VERSION ""

NS_ :

BS_:

BU_: Vector__XXX

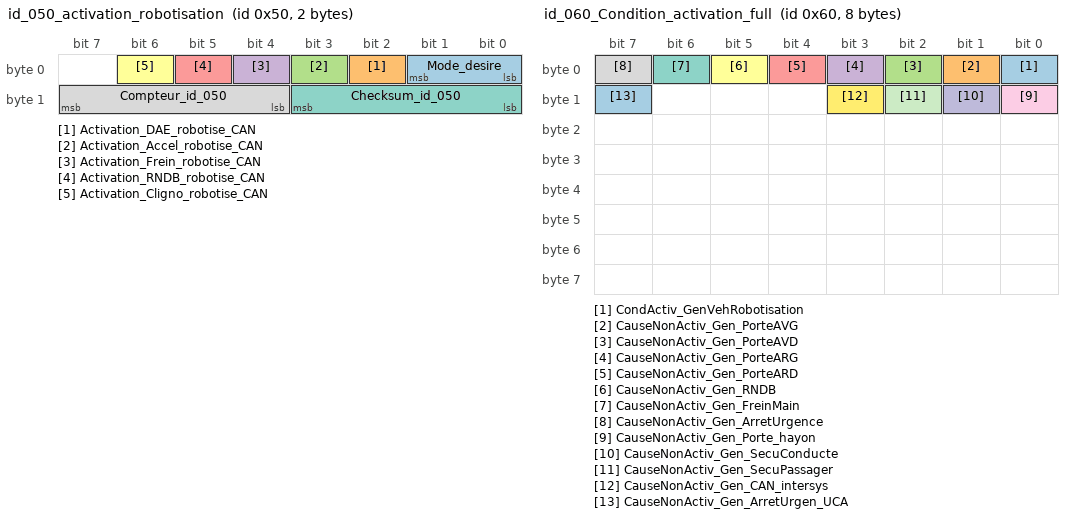
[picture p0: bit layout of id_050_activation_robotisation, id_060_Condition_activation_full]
BO_ 80 id_050_activation_robotisation: 2 Vector__XXX
SG_ Mode_desire : 1|2@0+ (1,0) [0|3] "-" Vector__XXX
SG_ Activation_DAE_robotise_CAN : 2|1@0+ (1,0) [0|1] "-" Vector__XXX
SG_ Activation_Accel_robotise_CAN : 3|1@0+ (1,0) [0|1] "-" Vector__XXX
SG_ Activation_Frein_robotise_CAN : 4|1@0+ (1,0) [0|1] "-" Vector__XXX
SG_ Activation_RNDB_robotise_CAN : 5|1@0+ (1,0) [0|1] "-" Vector__XXX
SG_ Activation_Cligno_robotise_CAN : 6|1@0+ (1,0) [0|1] "-" Vector__XXX
SG_ Checksum_id_050 : 11|4@0+ (1,0) [0|15] "CRC" Vector__XXX
SG_ Compteur_id_050 : 15|4@0+ (1,0) [0|15] "-" Vector__XXX

BO_ 96 id_060_Condition_activation_full: 8 Vector__XXX
SG_ CondActiv_GenVehRobotisation : 0|1@0+ (1,0) [0|1] "-" Vector__XXX
SG_ CauseNonActiv_Gen_PorteAVG : 1|1@0+ (1,0) [0|1] "-" Vector__XXX
SG_ CauseNonActiv_Gen_PorteAVD : 2|1@0+ (1,0) [0|1] "-" Vector__XXX
SG_ CauseNonActiv_Gen_PorteARG : 3|1@0+ (1,0) [0|1] "-" Vector__XXX
SG_ CauseNonActiv_Gen_PorteARD : 4|1@0+ (1,0) [0|1] "-" Vector__XXX
SG_ CauseNonActiv_Gen_RNDB : 5|1@0+ (1,0) [0|1] "-" Vector__XXX
SG_ CauseNonActiv_Gen_FreinMain : 6|1@0+ (1,0) [0|1] "-" Vector__XXX
SG_ CauseNonActiv_Gen_ArretUrgence : 7|1@0+ (1,0) [0|1] "-" Vector__XXX
SG_ CauseNonActiv_Gen_Porte_hayon : 8|1@0+ (1,0) [0|1] "-" Vector__XXX
SG_ CauseNonActiv_Gen_SecuConducte : 9|1@0+ (1,0) [0|1] "-" Vector__XXX
SG_ CauseNonActiv_Gen_SecuPassager : 10|1@0+ (1,0) [0|1] "-" Vector__XXX
SG_ CauseNonActiv_Gen_CAN_intersys : 11|1@0+ (1,0) [0|1] "-" Vector__XXX
SG_ CauseNonActiv_Gen_ArretUrgen_UCA : 15|1@0+ (1,0) [0|1] "-" Vector__XXX

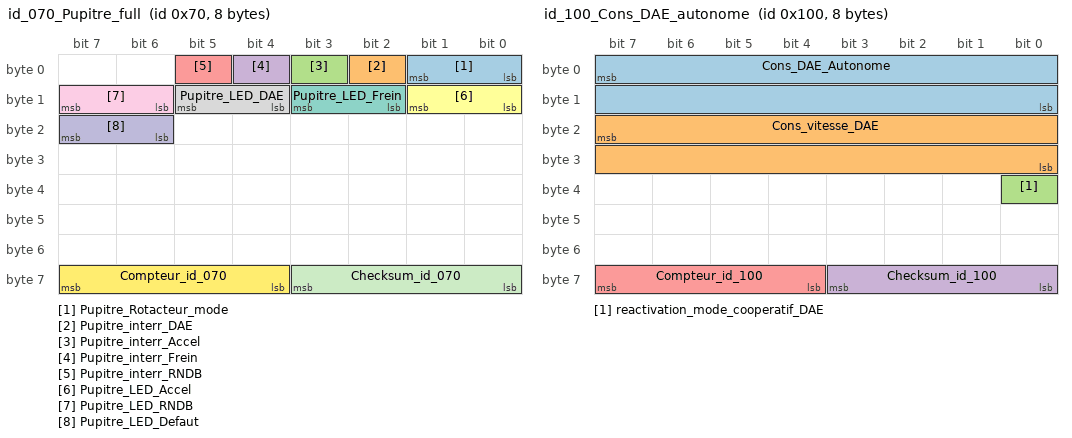
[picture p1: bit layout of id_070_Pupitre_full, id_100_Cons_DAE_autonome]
BO_ 112 id_070_Pupitre_full: 8 Vector__XXX
SG_ Pupitre_Rotacteur_mode : 1|2@0+ (1,0) [0|3] "-" Vector__XXX
SG_ Pupitre_interr_DAE : 2|1@0+ (1,0) [0|1] "-" Vector__XXX
SG_ Pupitre_interr_Accel : 3|1@0+ (1,0) [0|1] "-" Vector__XXX
SG_ Pupitre_interr_Frein : 4|1@0+ (1,0) [0|1] "-" Vector__XXX
SG_ Pupitre_interr_RNDB : 5|1@0+ (1,0) [0|1] "-" Vector__XXX
SG_ Pupitre_LED_Accel : 9|2@0+ (1,0) [0|3] "-" Vector__XXX
SG_ Pupitre_LED_Frein : 11|2@0+ (1,0) [0|3] "-" Vector__XXX
SG_ Pupitre_LED_DAE : 13|2@0+ (1,0) [0|3] "-" Vector__XXX
SG_ Pupitre_LED_RNDB : 15|2@0+ (1,0) [0|3] "-" Vector__XXX
SG_ Pupitre_LED_Defaut : 23|2@0+ (1,0) [0|3] "-" Vector__XXX
SG_ Checksum_id_070 : 59|4@0+ (1,0) [0|15] "CRC" Vector__XXX
SG_ Compteur_id_070 : 63|4@0+ (1,0) [0|15] "-" Vector__XXX

BO_ 256 id_100_Cons_DAE_autonome: 8 Vector__XXX
SG_ Cons_DAE_Autonome : 7|16@0+ (0.1,-720) [-720|5833.5] "°volant" Vector__XXX
SG_ Cons_vitesse_DAE : 23|16@0+ (0.1,0) [0|6553.5] "°/s" Vector__XXX
SG_ reactivation_mode_cooperatif_DAE : 32|1@0+ (1,0) [0|1] "-" Vector__XXX
SG_ Checksum_id_100 : 59|4@0+ (1,0) [0|15] "CRC" Vector__XXX
SG_ Compteur_id_100 : 63|4@0+ (1,0) [0|15] "-" Vector__XXX

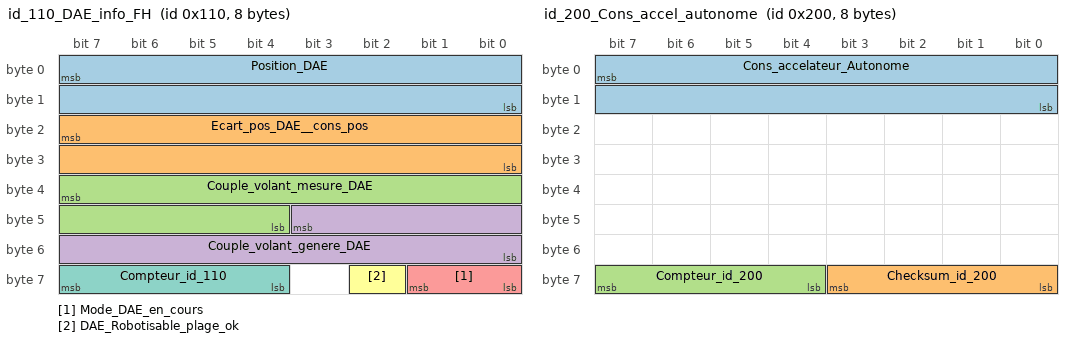
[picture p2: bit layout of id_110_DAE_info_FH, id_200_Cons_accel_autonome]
BO_ 272 id_110_DAE_info_FH: 8 Vector__XXX
SG_ Position_DAE : 7|16@0+ (0.1,-720) [-720|5833.5] "°volant" Vector__XXX
SG_ Ecart_pos_DAE__cons_pos : 23|16@0+ (0.1,-720) [-720|5833.5] "°volant" Vector__XXX
SG_ Couple_volant_mesure_DAE : 39|12@0+ (0.1,-200) [-200|209.5] "%" Vector__XXX
SG_ Couple_volant_genere_DAE : 43|12@0+ (0.1,-200) [-200|209.5] "%" Vector__XXX
SG_ Mode_DAE_en_cours : 57|2@0+ (1,0) [0|3] "-" Vector__XXX
SG_ DAE_Robotisable_plage_ok : 58|1@0+ (1,0) [0|1] "-" Vector__XXX
SG_ Compteur_id_110 : 63|4@0+ (1,0) [0|15] "-" Vector__XXX

BO_ 273 id_111_DAE_info_FH: 8 Vector__XXX
SG_ Butee_maxi_DAE_G_autorise : 7|16@0+ (0.1,-720) [-720|5833.5] "°volant" Vector__XXX
SG_ Butee_maxi_DAE_D_autorise : 23|16@0+ (0.1,-720) [-720|5833.5] "°volant" Vector__XXX
SG_ ErreurButeeDAE_gauche_atteinte : 32|1@0+ (1,0) [0|1] "-" Vector__XXX
SG_ ErreurButeeDAE_droite_atteinte : 33|1@0+ (1,0) [0|1] "-" Vector__XXX
SG_ ErreurCaptDAE_origine_couple_1 : 34|1@0+ (1,0) [0|1] "-" Vector__XXX
SG_ ErreurCapteur_DAE_incoh_sign1_2 : 35|1@0+ (1,0) [0|1] "-" Vector__XXX
SG_ ErreurPerte_CAN_intersystem_DAE : 36|1@0+ (1,0) [0|1] "-" Vector__XXX
SG_ CauseDesactDAE_RepriseManu : 40|1@0+ (1,0) [0|1] "-" Vector__XXX
SG_ CauseDesactDAE_RepriseExterne : 41|1@0+ (1,0) [0|1] "-" Vector__XXX
SG_ CauseDesactDAE_PbCANRot_timeout : 42|1@0+ (1,0) [0|1] "-" Vector__XXX
SG_ CauseDesactDAE_PbCANRob_chk : 43|1@0+ (1,0) [0|1] "-" Vector__XXX
SG_ CauseDesactDAE_PbCANRob_Cpt : 44|1@0+ (1,0) [0|1] "-" Vector__XXX
SG_ CauseDesactDAE_PbCapteurOri : 45|1@0+ (1,0) [0|1] "-" Vector__XXX
SG_ CauseDesactDAE_RepriseManuCoop : 46|1@0+ (1,0) [0|1] "-" Vector__XXX
SG_ DAE_DmdPilotageLED : 49|2@0+ (1,0) [0|3] "-" Vector__XXX
SG_ DAE_DmdPilotageBuzzer : 52|3@0+ (1,0) [0|7] "-" Vector__XXX
SG_ DAE_DmdPilotageLED_Dft : 54|2@0+ (1,0) [0|3] "-" Vector__XXX
SG_ Compteur_id_111 : 63|4@0+ (1,0) [0|15] "-" Vector__XXX

BO_ 512 id_200_Cons_accel_autonome: 8 Vector__XXX
SG_ Cons_accelateur_Autonome : 7|16@0+ (0.1,0) [0|6553.5] "0-100%" Vector__XXX
SG_ Checksum_id_200 : 59|4@0+ (1,0) [0|15] "CRC" Vector__XXX
SG_ Compteur_id_200 : 63|4@0+ (1,0) [0|15] "-" Vector__XXX

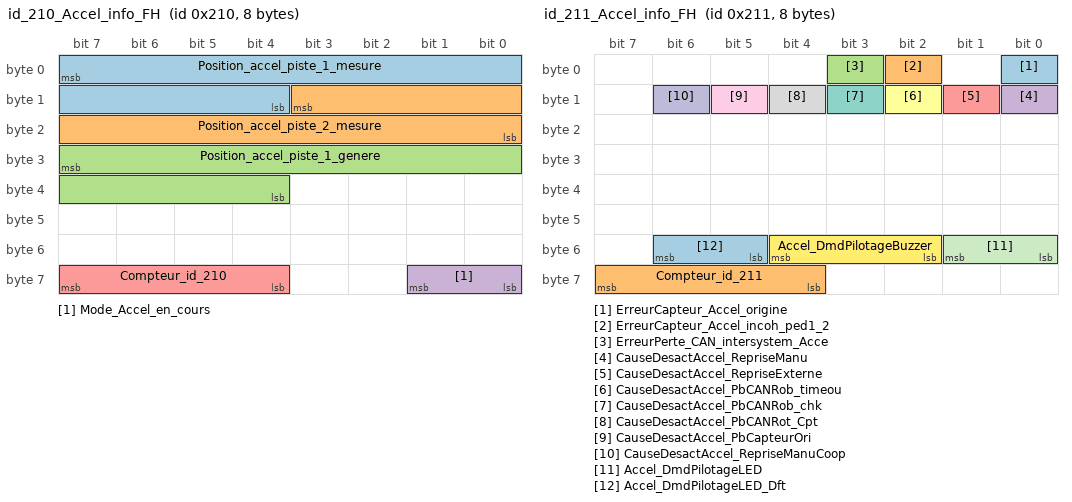
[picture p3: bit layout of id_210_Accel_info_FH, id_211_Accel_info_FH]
BO_ 528 id_210_Accel_info_FH: 8 Vector__XXX
SG_ Position_accel_piste_1_mesure : 7|12@0+ (0.1,0) [0|409.5] "0-100%" Vector__XXX
SG_ Position_accel_piste_2_mesure : 11|12@0+ (0.1,0) [0|409.5] "0-100%" Vector__XXX
SG_ Position_accel_piste_1_genere : 31|12@0+ (0.1,0) [0|409.5] "0-100%" Vector__XXX
SG_ Mode_Accel_en_cours : 57|2@0+ (1,0) [0|3] "-" Vector__XXX
SG_ Compteur_id_210 : 63|4@0+ (1,0) [0|15] "-" Vector__XXX

BO_ 529 id_211_Accel_info_FH: 8 Vector__XXX
SG_ ErreurCapteur_Accel_origine : 0|1@0+ (1,0) [0|1] "-" Vector__XXX
SG_ ErreurCapteur_Accel_incoh_ped1_2 : 2|1@0+ (1,0) [0|1] "-" Vector__XXX
SG_ ErreurPerte_CAN_intersystem_Acce : 3|1@0+ (1,0) [0|1] "-" Vector__XXX
SG_ CauseDesactAccel_RepriseManu : 8|1@0+ (1,0) [0|1] "-" Vector__XXX
SG_ CauseDesactAccel_RepriseExterne : 9|1@0+ (1,0) [0|1] "-" Vector__XXX
SG_ CauseDesactAccel_PbCANRob_timeou : 10|1@0+ (1,0) [0|1] "-" Vector__XXX
SG_ CauseDesactAccel_PbCANRob_chk : 11|1@0+ (1,0) [0|1] "-" Vector__XXX
SG_ CauseDesactAccel_PbCANRot_Cpt : 12|1@0+ (1,0) [0|1] "-" Vector__XXX
SG_ CauseDesactAccel_PbCapteurOri : 13|1@0+ (1,0) [0|1] "-" Vector__XXX
SG_ CauseDesactAccel_RepriseManuCoop : 14|1@0+ (1,0) [0|1] "-" Vector__XXX
SG_ Accel_DmdPilotageLED : 49|2@0+ (1,0) [0|3] "-" Vector__XXX
SG_ Accel_DmdPilotageBuzzer : 52|3@0+ (1,0) [0|7] "-" Vector__XXX
SG_ Accel_DmdPilotageLED_Dft : 54|2@0+ (1,0) [0|3] "-" Vector__XXX
SG_ Compteur_id_211 : 63|4@0+ (1,0) [0|15] "-" Vector__XXX

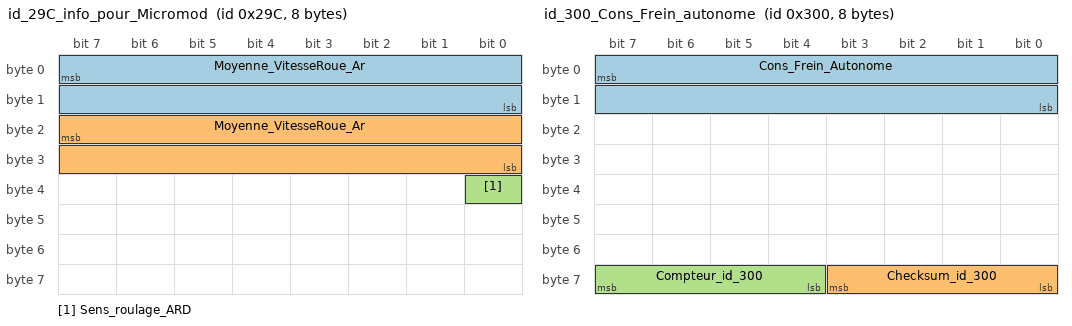
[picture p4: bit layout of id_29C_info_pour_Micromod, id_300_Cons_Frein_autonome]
BO_ 668 id_29C_info_pour_Micromod: 8 Vector__XXX
SG_ Moyenne_VitesseRoue_Ar : 7|16@0+ (0.0417,0) [0|2732.8095] "rpmg" Vector__XXX
SG_ Moyenne_VitesseRoue_Ar : 23|16@0+ (0.0417,0) [0|2732.8095] "rpmd" Vector__XXX
SG_ Sens_roulage_ARD : 32|1@0+ (1,0) [0|1] "-" Vector__XXX

BO_ 768 id_300_Cons_Frein_autonome: 8 Vector__XXX
SG_ Cons_Frein_Autonome : 7|16@0+ (0.1,0) [0|6553.5] "bars" Vector__XXX
SG_ Checksum_id_300 : 59|4@0+ (1,0) [0|15] "CRC" Vector__XXX
SG_ Compteur_id_300 : 63|4@0+ (1,0) [0|15] "-" Vector__XXX

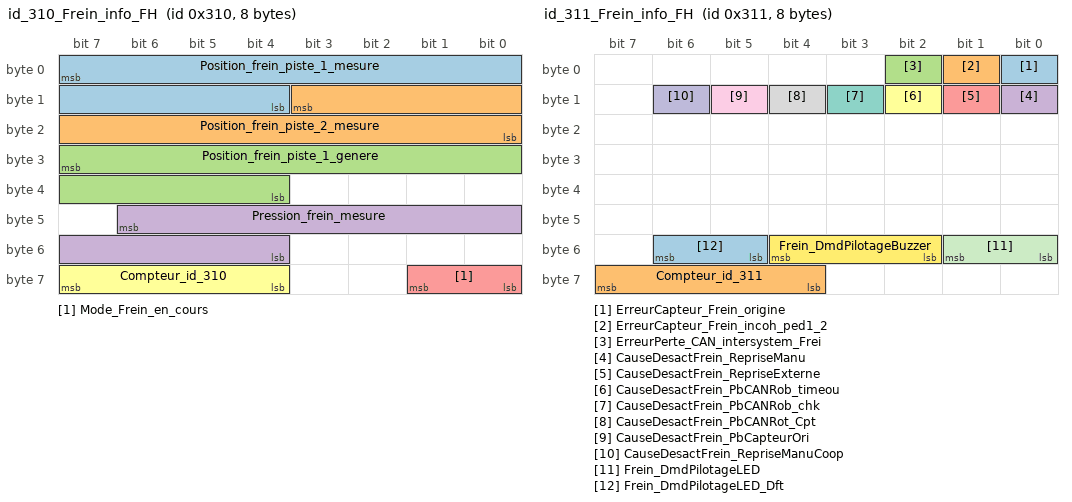
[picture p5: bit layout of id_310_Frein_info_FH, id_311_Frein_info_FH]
BO_ 784 id_310_Frein_info_FH: 8 Vector__XXX
SG_ Position_frein_piste_1_mesure : 7|12@0+ (1,0) [0|4095] "SENT" Vector__XXX
SG_ Position_frein_piste_2_mesure : 11|12@0+ (1,0) [0|4095] "µs" Vector__XXX
SG_ Position_frein_piste_1_genere : 31|12@0+ (1,0) [0|4095] "SENT" Vector__XXX
SG_ Pression_frein_mesure : 46|11@0+ (0.1,0) [0|204.7] "bars" Vector__XXX
SG_ Mode_Frein_en_cours : 57|2@0+ (1,0) [0|3] "-" Vector__XXX
SG_ Compteur_id_310 : 63|4@0+ (1,0) [0|15] "-" Vector__XXX

BO_ 785 id_311_Frein_info_FH: 8 Vector__XXX
SG_ ErreurCapteur_Frein_origine : 0|1@0+ (1,0) [0|1] "-" Vector__XXX
SG_ ErreurCapteur_Frein_incoh_ped1_2 : 1|1@0+ (1,0) [0|1] "-" Vector__XXX
SG_ ErreurPerte_CAN_intersystem_Frei : 2|1@0+ (1,0) [0|1] "-" Vector__XXX
SG_ CauseDesactFrein_RepriseManu : 8|1@0+ (1,0) [0|1] "-" Vector__XXX
SG_ CauseDesactFrein_RepriseExterne : 9|1@0+ (1,0) [0|1] "-" Vector__XXX
SG_ CauseDesactFrein_PbCANRob_timeou : 10|1@0+ (1,0) [0|1] "-" Vector__XXX
SG_ CauseDesactFrein_PbCANRob_chk : 11|1@0+ (1,0) [0|1] "-" Vector__XXX
SG_ CauseDesactFrein_PbCANRot_Cpt : 12|1@0+ (1,0) [0|1] "-" Vector__XXX
SG_ CauseDesactFrein_PbCapteurOri : 13|1@0+ (1,0) [0|1] "-" Vector__XXX
SG_ CauseDesactFrein_RepriseManuCoop : 14|1@0+ (1,0) [0|1] "-" Vector__XXX
SG_ Frein_DmdPilotageLED : 49|2@0+ (1,0) [0|3] "-" Vector__XXX
SG_ Frein_DmdPilotageBuzzer : 52|3@0+ (1,0) [0|7] "-" Vector__XXX
SG_ Frein_DmdPilotageLED_Dft : 54|2@0+ (1,0) [0|3] "-" Vector__XXX
SG_ Compteur_id_311 : 63|4@0+ (1,0) [0|15] "-" Vector__XXX

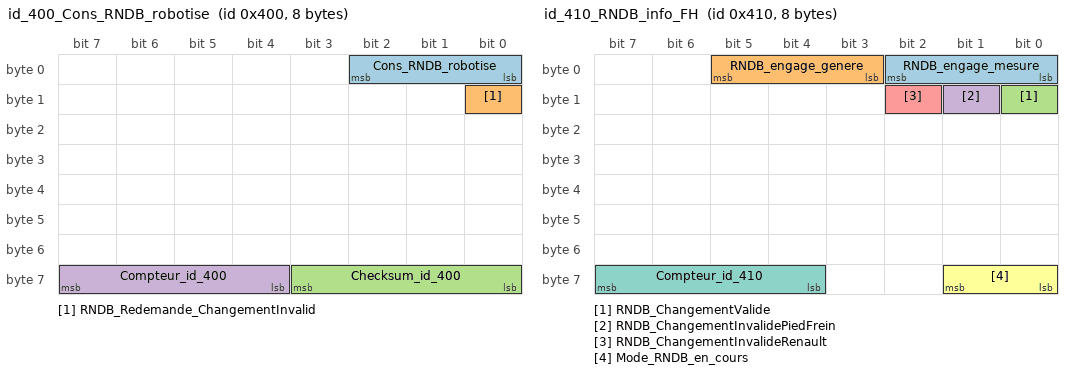
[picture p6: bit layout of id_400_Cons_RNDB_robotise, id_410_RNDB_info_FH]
BO_ 1024 id_400_Cons_RNDB_robotise: 8 Vector__XXX
SG_ Cons_RNDB_robotise : 2|3@0+ (1,0) [0|7] "-" Vector__XXX
SG_ RNDB_Redemande_ChangementInvalid : 8|1@0+ (1,0) [0|1] "-" Vector__XXX
SG_ Checksum_id_400 : 59|4@0+ (1,0) [0|15] "CRC" Vector__XXX
SG_ Compteur_id_400 : 63|4@0+ (1,0) [0|15] "-" Vector__XXX

BO_ 1040 id_410_RNDB_info_FH: 8 Vector__XXX
SG_ RNDB_engage_mesure : 2|3@0+ (1,0) [0|7] "-" Vector__XXX
SG_ RNDB_engage_genere : 5|3@0+ (1,0) [0|7] "-" Vector__XXX
SG_ RNDB_ChangementValide : 8|1@0+ (1,0) [0|1] "-" Vector__XXX
SG_ RNDB_ChangementInvalidePiedFrein : 9|1@0+ (1,0) [0|1] "-" Vector__XXX
SG_ RNDB_ChangementInvalideRenault : 10|1@0+ (1,0) [0|1] "-" Vector__XXX
SG_ Mode_RNDB_en_cours : 57|2@0+ (1,0) [0|3] "-" Vector__XXX
SG_ Compteur_id_410 : 63|4@0+ (1,0) [0|15] "-" Vector__XXX

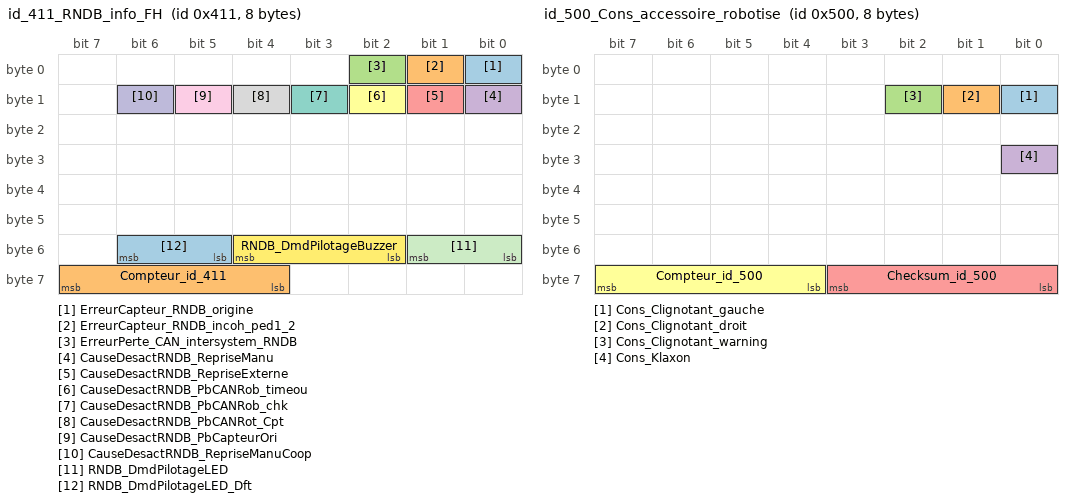
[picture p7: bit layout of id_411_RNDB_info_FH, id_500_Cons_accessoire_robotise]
BO_ 1041 id_411_RNDB_info_FH: 8 Vector__XXX
SG_ ErreurCapteur_RNDB_origine : 0|1@0+ (1,0) [0|1] "-" Vector__XXX
SG_ ErreurCapteur_RNDB_incoh_ped1_2 : 1|1@0+ (1,0) [0|1] "-" Vector__XXX
SG_ ErreurPerte_CAN_intersystem_RNDB : 2|1@0+ (1,0) [0|1] "-" Vector__XXX
SG_ CauseDesactRNDB_RepriseManu : 8|1@0+ (1,0) [0|1] "-" Vector__XXX
SG_ CauseDesactRNDB_RepriseExterne : 9|1@0+ (1,0) [0|1] "-" Vector__XXX
SG_ CauseDesactRNDB_PbCANRob_timeou : 10|1@0+ (1,0) [0|1] "-" Vector__XXX
SG_ CauseDesactRNDB_PbCANRob_chk : 11|1@0+ (1,0) [0|1] "-" Vector__XXX
SG_ CauseDesactRNDB_PbCANRot_Cpt : 12|1@0+ (1,0) [0|1] "-" Vector__XXX
SG_ CauseDesactRNDB_PbCapteurOri : 13|1@0+ (1,0) [0|1] "-" Vector__XXX
SG_ CauseDesactRNDB_RepriseManuCoop : 14|1@0+ (1,0) [0|1] "-" Vector__XXX
SG_ RNDB_DmdPilotageLED : 49|2@0+ (1,0) [0|3] "-" Vector__XXX
SG_ RNDB_DmdPilotageBuzzer : 52|3@0+ (1,0) [0|7] "-" Vector__XXX
SG_ RNDB_DmdPilotageLED_Dft : 54|2@0+ (1,0) [0|3] "-" Vector__XXX
SG_ Compteur_id_411 : 63|4@0+ (1,0) [0|15] "-" Vector__XXX

BO_ 1280 id_500_Cons_accessoire_robotise: 8 Vector__XXX
SG_ Cons_Clignotant_gauche : 8|1@0+ (1,0) [0|1] "-" Vector__XXX
SG_ Cons_Clignotant_droit : 9|1@0+ (1,0) [0|1] "-" Vector__XXX
SG_ Cons_Clignotant_warning : 10|1@0+ (1,0) [0|1] "-" Vector__XXX
SG_ Cons_Klaxon : 24|1@0+ (1,0) [0|1] "-" Vector__XXX
SG_ Checksum_id_500 : 59|4@0+ (1,0) [0|15] "CRC" Vector__XXX
SG_ Compteur_id_500 : 63|4@0+ (1,0) [0|15] "-" Vector__XXX

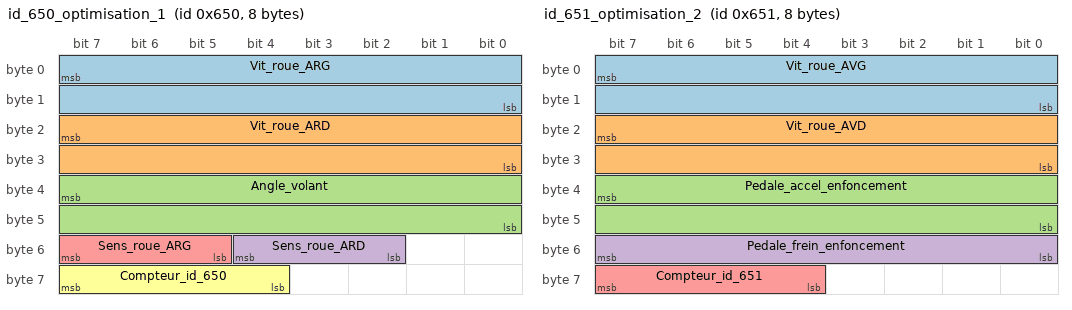
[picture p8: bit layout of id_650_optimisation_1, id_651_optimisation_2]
BO_ 1616 id_650_optimisation_1: 8 Vector__XXX
SG_ Vit_roue_ARG : 7|16@0+ (0.5,0) [0|32767.5] "tr/min" Vector__XXX
SG_ Vit_roue_ARD : 23|16@0+ (0.5,0) [0|32767.5] "tr/min" Vector__XXX
SG_ Angle_volant : 39|16@0- (0.1,0) [-3276.8|3276.7] "°" Vector__XXX
SG_ Sens_roue_ARD : 52|3@0+ (1,0) [0|7] "-" Vector__XXX
SG_ Sens_roue_ARG : 55|3@0+ (1,0) [0|7] "-" Vector__XXX
SG_ Compteur_id_650 : 63|4@0+ (1,0) [0|15] "-" Vector__XXX

BO_ 1617 id_651_optimisation_2: 8 Vector__XXX
SG_ Vit_roue_AVG : 7|16@0+ (0.5,0) [0|32767.5] "tr/min" Vector__XXX
SG_ Vit_roue_AVD : 23|16@0+ (0.5,0) [0|32767.5] "tr/min" Vector__XXX
SG_ Pedale_accel_enfoncement : 39|16@0+ (0.1,0) [0|6553.5] "%" Vector__XXX
SG_ Pedale_frein_enfoncement : 55|8@0+ (1,0) [0|255] "???" Vector__XXX
SG_ Compteur_id_651 : 63|4@0+ (1,0) [0|15] "-" Vector__XXX

BO_ 1618 id_652_optimisation_3: 8 Vector__XXX
SG_ FeuxVeilleuses_commodo : 0|1@0+ (1,0) [0|1] "-" Vector__XXX
SG_ FeuxCodes_commodo : 1|1@0+ (1,0) [0|1] "-" Vector__XXX
SG_ FeuxRoute_commodo : 2|1@0+ (1,0) [0|1] "-" Vector__XXX
SG_ FeuxBrouillardAR_commodo : 4|1@0+ (1,0) [0|1] "-" Vector__XXX
SG_ FeuxClignotantG_commodo : 5|1@0+ (1,0) [0|1] "-" Vector__XXX
SG_ FeuxClignotantD_commodo : 6|1@0+ (1,0) [0|1] "-" Vector__XXX
SG_ FeuxWarning_commodo : 7|1@0+ (1,0) [0|1] "-" Vector__XXX
SG_ FeuxVeilleuses_etat : 8|1@0+ (1,0) [0|1] "-" Vector__XXX
SG_ FeuxCodes_etat : 9|1@0+ (1,0) [0|1] "-" Vector__XXX
SG_ FeuxRoute_etat : 10|1@0+ (1,0) [0|1] "-" Vector__XXX
SG_ FeuxBrouillardAR_etat : 12|1@0+ (1,0) [0|1] "-" Vector__XXX
SG_ FeuxClignotantG_etat : 13|1@0+ (1,0) [0|1] "-" Vector__XXX
SG_ FeuxClignotantD_etat : 14|1@0+ (1,0) [0|1] "-" Vector__XXX
SG_ FeuxWarning_etat : 15|1@0+ (1,0) [0|1] "-" Vector__XXX
SG_ OuvrantPortiereAVG_etat : 16|1@0+ (1,0) [0|1] "-" Vector__XXX
SG_ OuvrantPortiereAVD_etat : 17|1@0+ (1,0) [0|1] "-" Vector__XXX
SG_ OuvrantPortiereARG_etat : 18|1@0+ (1,0) [0|1] "-" Vector__XXX
SG_ OuvrantPortiereARD_etat : 19|1@0+ (1,0) [0|1] "-" Vector__XXX
SG_ OuvrantCoffreAR_etat : 21|1@0+ (1,0) [0|1] "-" Vector__XXX
SG_ CeintureSecurite_ConducteuEnSecu : 24|1@0+ (1,0) [0|1] "-" Vector__XXX
SG_ CeintureSecurite_PassagerEnSecu : 25|1@0+ (1,0) [0|1] "-" Vector__XXX
SG_ CeintureSecurite_ARG : 26|1@0+ (1,0) [0|1] "-" Vector__XXX
SG_ CeintureSecurite_ARD : 27|1@0+ (1,0) [0|1] "-" Vector__XXX
SG_ CeintureSecurite_ARC : 28|1@0+ (1,0) [0|1] "-" Vector__XXX
SG_ EssuiesGlaceVitPetite_commodo : 32|1@0+ (1,0) [0|1] "-" Vector__XXX
SG_ EssuiesGlaceVitGrande_commodo : 33|1@0+ (1,0) [0|1] "-" Vector__XXX
SG_ EssuiesGlaceVitPetite_etat : 34|1@0+ (1,0) [0|1] "-" Vector__XXX
SG_ EssuiesGlaceVitGrande_etat : 35|1@0+ (1,0) [0|1] "-" Vector__XXX
SG_ Position_RNDB : 50|3@0+ (1,0) [0|7] "-" Vector__XXX
SG_ Etat_pedale_Frein : 53|1@0+ (1,0) [0|1] "-" Vector__XXX
SG_ Etat_pedale_Accel : 54|1@0+ (1,0) [0|1] "-" Vector__XXX
SG_ Etat_Frein_a_main : 55|1@0+ (1,0) [0|1] "-" Vector__XXX
SG_ Compteur_id_652 : 63|4@0+ (1,0) [0|15] "-" Vector__XXX

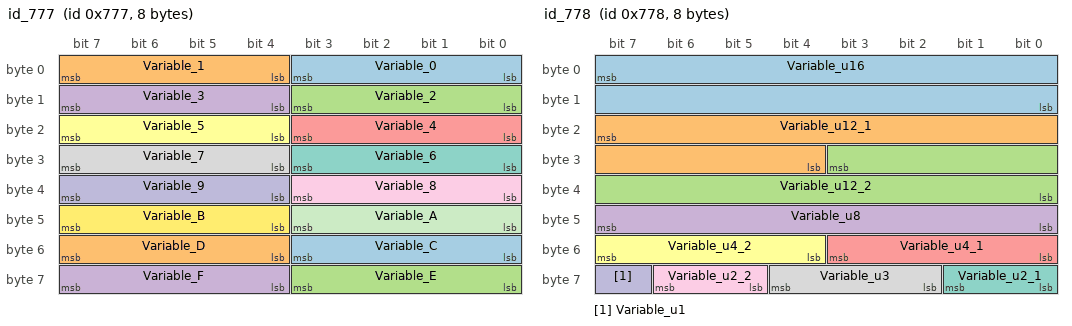
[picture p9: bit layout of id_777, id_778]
BO_ 1911 id_777: 8 Vector__XXX
SG_ Variable_0 : 3|4@0+ (1,0) [0|15] "" Vector__XXX
SG_ Variable_1 : 7|4@0+ (1,0) [0|15] "" Vector__XXX
SG_ Variable_2 : 11|4@0+ (1,0) [0|15] "" Vector__XXX
SG_ Variable_3 : 15|4@0+ (1,0) [0|15] "" Vector__XXX
SG_ Variable_4 : 19|4@0+ (1,0) [0|15] "" Vector__XXX
SG_ Variable_5 : 23|4@0+ (1,0) [0|15] "" Vector__XXX
SG_ Variable_6 : 27|4@0+ (1,0) [0|15] "" Vector__XXX
SG_ Variable_7 : 31|4@0+ (1,0) [0|15] "" Vector__XXX
SG_ Variable_8 : 35|4@0+ (1,0) [0|15] "" Vector__XXX
SG_ Variable_9 : 39|4@0+ (1,0) [0|15] "" Vector__XXX
SG_ Variable_A : 43|4@0+ (1,0) [0|15] "" Vector__XXX
SG_ Variable_B : 47|4@0+ (1,0) [0|15] "" Vector__XXX
SG_ Variable_C : 51|4@0+ (1,0) [0|15] "" Vector__XXX
SG_ Variable_D : 55|4@0+ (1,0) [0|15] "" Vector__XXX
SG_ Variable_E : 59|4@0+ (1,0) [0|15] "" Vector__XXX
SG_ Variable_F : 63|4@0+ (1,0) [0|15] "" Vector__XXX

BO_ 1912 id_778: 8 Vector__XXX
SG_ Variable_u16 : 7|16@0+ (1,0) [0|65535] "" Vector__XXX
SG_ Variable_u12_1 : 23|12@0+ (1,0) [0|4095] "" Vector__XXX
SG_ Variable_u12_2 : 27|12@0+ (1,0) [0|4095] "" Vector__XXX
SG_ Variable_u8 : 47|8@0+ (1,0) [0|255] "" Vector__XXX
SG_ Variable_u4_1 : 51|4@0+ (1,0) [0|15] "" Vector__XXX
SG_ Variable_u4_2 : 55|4@0+ (1,0) [0|15] "" Vector__XXX
SG_ Variable_u2_1 : 57|2@0+ (1,0) [0|3] "" Vector__XXX
SG_ Variable_u3 : 60|3@0+ (1,0) [0|7] "" Vector__XXX
SG_ Variable_u2_2 : 62|2@0+ (1,0) [0|3] "" Vector__XXX
SG_ Variable_u1 : 63|1@0+ (1,0) [0|1] "" Vector__XXX

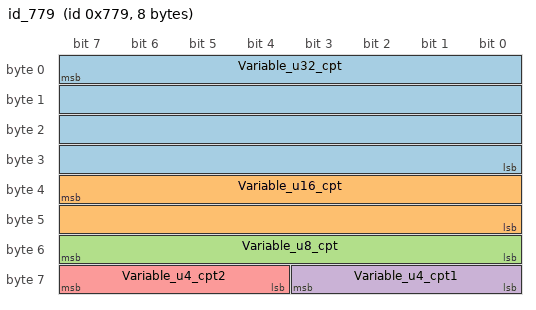
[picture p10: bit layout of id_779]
BO_ 1913 id_779: 8 Vector__XXX
SG_ Variable_u32_cpt : 7|32@0+ (1,0) [0|4294967295] "" Vector__XXX
SG_ Variable_u16_cpt : 39|16@0+ (1,0) [0|65535] "" Vector__XXX
SG_ Variable_u8_cpt : 55|8@0+ (1,0) [0|255] "" Vector__XXX
SG_ Variable_u4_cpt1 : 59|4@0+ (1,0) [0|15] "" Vector__XXX
SG_ Variable_u4_cpt2 : 63|4@0+ (1,0) [0|15] "" Vector__XXX

CM_ BO_ 80 "PC robotisation vers boitier FH";
CM_ SG_ 80 Mode_desire "Choix du mode de roulage via le CAN";
CM_ SG_ 80 Activation_DAE_robotise_CAN "Activation de la commande via le CAN";
CM_ SG_ 80 Activation_Accel_robotise_CAN "Activation de la commande via le CAN";
CM_ SG_ 80 Activation_Frein_robotise_CAN "Activation de la commande via le CAN";
CM_ SG_ 80 Activation_RNDB_robotise_CAN "Activation de la commande via le CAN";
CM_ SG_ 80 Activation_Cligno_robotise_CAN "Activation de la commande via le CAN";
CM_ SG_ 80 Checksum_id_050 "cryptage pour validation du contenu de la trame";
CM_ SG_ 80 Compteur_id_050 "compteur de 0 à 15 (0-F)";
CM_ BO_ 96 "boitier FH vers PC robotisation";
CM_ SG_ 96 CondActiv_GenVehRobotisation "Activation de la robotisation en fonction des conditions vehicule";
CM_ SG_ 96 CauseNonActiv_Gen_PorteAVG "Activation de la robotisation en fonction de la fermeture Porte AVG";
CM_ SG_ 96 CauseNonActiv_Gen_PorteAVD "Activation de la robotisation en fonction de la fermeture Porte AVD";
CM_ SG_ 96 CauseNonActiv_Gen_PorteARG "Activation de la robotisation en fonction de la fermeture Porte ARG";
CM_ SG_ 96 CauseNonActiv_Gen_PorteARD "Activation de la robotisation en fonction de la fermeture Porte ARD";
CM_ SG_ 96 CauseNonActiv_Gen_RNDB "Activation de la robotisation en fonction de la position RNDB";
CM_ SG_ 96 CauseNonActiv_Gen_FreinMain "Activation de la robotisation en fonction de la position du frein a main";
CM_ SG_ 96 CauseNonActiv_Gen_ArretUrgence "Activation de la robotisation en fonction de l arret urgence";
CM_ SG_ 96 CauseNonActiv_Gen_Porte_hayon "Activation de la robotisation en fonction de la fermeture du hayon";
CM_ SG_ 96 CauseNonActiv_Gen_SecuConducte "Activation de la robotisation en fonction de la securite du conducteur - ceinture";
CM_ SG_ 96 CauseNonActiv_Gen_SecuPassager "Activation de la robotisation en fonction de la securite du passager - ceinture";
CM_ SG_ 96 CauseNonActiv_Gen_CAN_intersys "Activation de la robotisation en fonction de la validite du CAN Veh";
CM_ SG_ 96 CauseNonActiv_Gen_ArretUrgen_UCA "Activation de la robotisation en fonction de l arret urgence UCA";
CM_ BO_ 112 "boitier FH vers PC robotisation";
CM_ SG_ 112 Pupitre_Rotacteur_mode "Pupitre : etat du rotacteur";
CM_ SG_ 112 Pupitre_interr_DAE "Pupitre : etat de l interrupteur";
CM_ SG_ 112 Pupitre_interr_Accel "Pupitre : etat de l interrupteur";
CM_ SG_ 112 Pupitre_interr_Frein "Pupitre : etat de l interrupteur";
CM_ SG_ 112 Pupitre_interr_RNDB "Pupitre : etat de l interrupteur";
CM_ SG_ 112 Pupitre_LED_Accel "Pupitre : etat de LED";
CM_ SG_ 112 Pupitre_LED_Frein "Pupitre : etat de LED";
CM_ SG_ 112 Pupitre_LED_DAE "Pupitre : etat de LED";
CM_ SG_ 112 Pupitre_LED_RNDB "Pupitre : etat de LED";
CM_ SG_ 112 Pupitre_LED_Defaut "Pupitre : etat de LED";
CM_ SG_ 112 Checksum_id_070 "cryptage pour validation du contenu de la trame";
CM_ SG_ 112 Compteur_id_070 "compteur de 0 à 15 (0-F)";
CM_ BO_ 256 "PC robotisation vers boitier FH";
CM_ SG_ 256 Cons_DAE_Autonome "consigne de position de la direction";
CM_ SG_ 256 Cons_vitesse_DAE "consigne de vitesse de rotation de la direction";
CM_ SG_ 256 reactivation_mode_cooperatif_DAE "Reactivation de la DAE rapide en cas de desactivation";
CM_ SG_ 256 Checksum_id_100 "cryptage pour validation du contenu de la trame";
CM_ SG_ 256 Compteur_id_100 "compteur de 0 à 15 (0-F)";
CM_ BO_ 272 "boitier FH vers PC robotisation";
CM_ SG_ 272 Position_DAE "Position mesurée du volant";
CM_ SG_ 272 Ecart_pos_DAE__cons_pos "ecart de position du volant entre la consigne et sa position";
CM_ SG_ 272 Couple_volant_mesure_DAE "Couple mesuré sur le volant exercé par le conducteur";
CM_ SG_ 272 Couple_volant_genere_DAE "Pseudo couple sur volant generé par FH pour robotiser la DAE";
CM_ SG_ 272 Mode_DAE_en_cours "mode en cours";
CM_ SG_ 272 DAE_Robotisable_plage_ok "La consigne CAN d'angle volant est proche de la mesure de l angle volant";
CM_ SG_ 272 Compteur_id_110 "compteur de 0 à 15 (0-F)";
CM_ BO_ 273 "boitier FH vers PC robotisation";
CM_ SG_ 273 Butee_maxi_DAE_G_autorise "Valeur maxi que la direction peut accepter (butée)";
CM_ SG_ 273 Butee_maxi_DAE_D_autorise "Valeur maxi que la direction peut accepter (butée)";
CM_ SG_ 273 ErreurButeeDAE_gauche_atteinte "erreur : desactivation suite position en butée maxi";
CM_ SG_ 273 ErreurButeeDAE_droite_atteinte "erreur : desactivation suite position en butée maxi";
CM_ SG_ 273 ErreurCaptDAE_origine_couple_1 "erreur : desactivation suite erreur sur le capteur couple 1 d origine";
CM_ SG_ 273 ErreurCapteur_DAE_incoh_sign1_2 "erreur : desactivation suite erreur de coherence entre les 2 pistes du couple d origine";
CM_ SG_ 273 ErreurPerte_CAN_intersystem_DAE "erreur : desactivation suite perte du CAN Intersystem";
CM_ SG_ 273 CauseDesactDAE_RepriseManu "erreur : desactivation suite prise en main cette fonction robotisé";
CM_ SG_ 273 CauseDesactDAE_RepriseExterne "erreur : desactivation suite prise en main d'une fonction externe robotisé";
CM_ SG_ 273 CauseDesactDAE_PbCANRot_timeout "erreur : desactivation suite erreur timeout CAN";
CM_ SG_ 273 CauseDesactDAE_PbCANRob_chk "erreur : desactivation suite erreur de calcul du checksum";
CM_ SG_ 273 CauseDesactDAE_PbCANRob_Cpt "erreur : desactivation suite consigne hors limite autorisé";
CM_ SG_ 273 CauseDesactDAE_PbCapteurOri "erreur : desactivation suite erreur sur le capteur d origine";
CM_ SG_ 273 CauseDesactDAE_RepriseManuCoop "erreur : desactivation suite prise en main cette fonction Cooperatif";
CM_ SG_ 273 DAE_DmdPilotageLED "Demande de pilotage de la LED organe";
CM_ SG_ 273 DAE_DmdPilotageBuzzer "Demande de pilotage du buzzer";
CM_ SG_ 273 DAE_DmdPilotageLED_Dft "Demande de pilotage de la LED defaut";
CM_ SG_ 273 Compteur_id_111 "compteur de 0 à 15 (0-F)";
CM_ BO_ 512 "PC robotisation vers boitier FH";
CM_ SG_ 512 Cons_accelateur_Autonome "consigne de l accelerateur";
CM_ SG_ 512 Checksum_id_200 "cryptage pour validation du contenu de la trame";
CM_ SG_ 512 Compteur_id_200 "compteur de 0 à 15 (0-F)";
CM_ BO_ 528 "boitier FH vers PC robotisation";
CM_ SG_ 528 Position_accel_piste_1_mesure "Position accel (Ped1) mesurée par FH";
CM_ SG_ 528 Position_accel_piste_2_mesure "Position accel (Ped2) mesurée par FH";
CM_ SG_ 528 Position_accel_piste_1_genere "Pseudo position accel (Ped1) generée par FH";
CM_ SG_ 528 Mode_Accel_en_cours "mode en cours";
CM_ SG_ 528 Compteur_id_210 "compteur de 0 à 15 (0-F)";
CM_ BO_ 529 "boitier FH vers PC robotisation";
CM_ SG_ 529 ErreurCapteur_Accel_origine "erreur : desactivation suite erreur sur le capteur  d origine";
CM_ SG_ 529 ErreurCapteur_Accel_incoh_ped1_2 "erreur : desactivation suite erreur de coherence entre capteur ped1/ped2  d origine";
CM_ SG_ 529 ErreurPerte_CAN_intersystem_Acce "erreur : desactivation suite perte du CAN Intersystem";
CM_ SG_ 529 CauseDesactAccel_RepriseManu "erreur : desactivation suite prise en main cette fonction robotisé";
CM_ SG_ 529 CauseDesactAccel_RepriseExterne "erreur : desactivation suite prise en main d'une fonction externe robotisé";
CM_ SG_ 529 CauseDesactAccel_PbCANRob_timeou "erreur : desactivation suite erreur timeout CAN";
CM_ SG_ 529 CauseDesactAccel_PbCANRob_chk "erreur : desactivation suite erreur de calcul du checksum";
CM_ SG_ 529 CauseDesactAccel_PbCANRot_Cpt "erreur : desactivation suite consigne hors limite autorisé";
CM_ SG_ 529 CauseDesactAccel_PbCapteurOri "erreur : desactivation suite erreur sur le capteur d origine";
CM_ SG_ 529 CauseDesactAccel_RepriseManuCoop "erreur : desactivation suite prise en main cette fonction Cooperatif";
CM_ SG_ 529 Accel_DmdPilotageLED "Demande de pilotage de la LED organe";
CM_ SG_ 529 Accel_DmdPilotageBuzzer "Demande de pilotage du buzzer";
CM_ SG_ 529 Accel_DmdPilotageLED_Dft "Demande de pilotage de la LED defaut";
CM_ SG_ 529 Compteur_id_211 "compteur de 0 à 15 (0-F)";
CM_ BO_ 668 "info pour Micromod - top roue";
CM_ SG_ 668 Moyenne_VitesseRoue_Ar "Moyenne des roues arriere";
CM_ SG_ 668 Sens_roulage_ARD "Sens de roulage (marche avant ou pas marche avant)";
CM_ BO_ 768 "PC robotisation vers boitier FH";
CM_ SG_ 768 Cons_Frein_Autonome "consigne de position de la pedale de frein";
CM_ SG_ 768 Checksum_id_300 "cryptage pour validation du contenu de la trame";
CM_ SG_ 768 Compteur_id_300 "compteur de 0 à 15 (0-F)";
CM_ BO_ 784 "boitier FH vers PC robotisation";
CM_ SG_ 784 Position_frein_piste_1_mesure "Position frein (Ped1) mesurée par FH";
CM_ SG_ 784 Position_frein_piste_2_mesure "Position frein (Ped2) mesurée par FH";
CM_ SG_ 784 Position_frein_piste_1_genere "Pseudo position frein (Ped1) generée par FH";
CM_ SG_ 784 Mode_Frein_en_cours "mode en cours";
CM_ SG_ 784 Compteur_id_310 "compteur de 0 à 15 (0-F)";
CM_ BO_ 785 "boitier FH vers PC robotisation";
CM_ SG_ 785 ErreurCapteur_Frein_origine "erreur : desactivation suite erreur sur le capteur frein 1 d origine";
CM_ SG_ 785 ErreurCapteur_Frein_incoh_ped1_2 "erreur : desactivation suite erreur de coherence entre capteur ped1/ped2  d origine";
CM_ SG_ 785 ErreurPerte_CAN_intersystem_Frei "erreur : desactivation suite perte du CAN Intersystem";
CM_ SG_ 785 CauseDesactFrein_RepriseManu "erreur : desactivation suite prise en main cette fonction robotisé";
CM_ SG_ 785 CauseDesactFrein_RepriseExterne "erreur : desactivation suite prise en main d'une fonction externe robotisé";
CM_ SG_ 785 CauseDesactFrein_PbCANRob_timeou "erreur : desactivation suite erreur timeout CAN";
CM_ SG_ 785 CauseDesactFrein_PbCANRob_chk "erreur : desactivation suite erreur de calcul du checksum";
CM_ SG_ 785 CauseDesactFrein_PbCANRot_Cpt "erreur : desactivation suite consigne hors limite autorisé";
CM_ SG_ 785 CauseDesactFrein_PbCapteurOri "erreur : desactivation suite erreur sur le capteur d origine";
CM_ SG_ 785 CauseDesactFrein_RepriseManuCoop "erreur : desactivation suite prise en main cette fonction Cooperatif";
CM_ SG_ 785 Frein_DmdPilotageLED "Demande de pilotage de la LED organe";
CM_ SG_ 785 Frein_DmdPilotageBuzzer "Demande de pilotage du buzzer";
CM_ SG_ 785 Frein_DmdPilotageLED_Dft "Demande de pilotage de la LED defaut";
CM_ SG_ 785 Compteur_id_311 "compteur de 0 à 15 (0-F)";
CM_ BO_ 1024 "PC robotisation vers boitier FH";
CM_ SG_ 1024 Cons_RNDB_robotise "consigne du rapport a engager";
CM_ SG_ 1024 RNDB_Redemande_ChangementInvalid "RNDB permet de redemander le changement invalide precedent";
CM_ SG_ 1024 Checksum_id_400 "cryptage pour validation du contenu de la trame";
CM_ SG_ 1024 Compteur_id_400 "compteur de 0 à 15 (0-F)";
CM_ BO_ 1040 "boitier FH vers PC robotisation";
CM_ SG_ 1040 RNDB_engage_mesure "Rapport engage mesuré par FH";
CM_ SG_ 1040 RNDB_engage_genere "Pseudo rapport engage generé par FH";
CM_ SG_ 1040 RNDB_ChangementValide "RNDB dernier changement valide";
CM_ SG_ 1040 RNDB_ChangementInvalidePiedFrein "RNDB dernier changement non valide";
CM_ SG_ 1040 RNDB_ChangementInvalideRenault "RNDB dernier changement non valide";
CM_ SG_ 1040 Mode_RNDB_en_cours "mode en cours";
CM_ SG_ 1040 Compteur_id_410 "compteur de 0 à 15 (0-F)";
CM_ BO_ 1041 "boitier FH vers PC robotisation";
CM_ SG_ 1041 ErreurCapteur_RNDB_origine "erreur : desactivation suite erreur sur le capteur RNDB d origine";
CM_ SG_ 1041 ErreurCapteur_RNDB_incoh_ped1_2 "erreur : desactivation suite erreur de coherence entre les signaux capteur RNDB d origine";
CM_ SG_ 1041 ErreurPerte_CAN_intersystem_RNDB "erreur : desactivation suite perte du CAN Intersystem";
CM_ SG_ 1041 CauseDesactRNDB_RepriseManu "erreur : desactivation suite prise en main cette fonction robotisé";
CM_ SG_ 1041 CauseDesactRNDB_RepriseExterne "erreur : desactivation suite prise en main d'une fonction externe robotisé";
CM_ SG_ 1041 CauseDesactRNDB_PbCANRob_timeou "erreur : desactivation suite erreur timeout CAN";
CM_ SG_ 1041 CauseDesactRNDB_PbCANRob_chk "erreur : desactivation suite erreur de calcul du checksum";
CM_ SG_ 1041 CauseDesactRNDB_PbCANRot_Cpt "erreur : desactivation suite consigne hors limite autorisé";
CM_ SG_ 1041 CauseDesactRNDB_PbCapteurOri "erreur : desactivation suite erreur sur le capteur d origine";
CM_ SG_ 1041 CauseDesactRNDB_RepriseManuCoop "erreur : desactivation suite prise en main cette fonction Cooperatif";
CM_ SG_ 1041 RNDB_DmdPilotageLED "Demande de pilotage de la LED organe";
CM_ SG_ 1041 RNDB_DmdPilotageBuzzer "Demande de pilotage du buzzer";
CM_ SG_ 1041 RNDB_DmdPilotageLED_Dft "Demande de pilotage de la LED defaut";
CM_ SG_ 1041 Compteur_id_411 "compteur de 0 à 15 (0-F)";
CM_ BO_ 1280 "PC robotisation vers boitier FH";
CM_ SG_ 1280 Cons_Clignotant_gauche "consigne d activation du clignotant gauche";
CM_ SG_ 1280 Cons_Clignotant_droit "consigne d activation du clignotant droit";
CM_ SG_ 1280 Cons_Clignotant_warning "consigne d activation des warning (a confirmer si realisable sur ZE50 !!!!)";
CM_ SG_ 1280 Cons_Klaxon "consigne d activation du klaxon";
CM_ SG_ 1280 Checksum_id_500 "cryptage pour validation du contenu de la trame";
CM_ SG_ 1280 Compteur_id_500 "compteur de 0 à 15 (0-F)";
CM_ BO_ 1616 "boitier FH vers PC robotisation";
CM_ SG_ 1616 Vit_roue_ARG "Vitesse de la roue";
CM_ SG_ 1616 Vit_roue_ARD "Vitesse de la roue";
CM_ SG_ 1616 Angle_volant "Position mesurée du volant";
CM_ SG_ 1616 Sens_roue_ARD "Sens de roulage du vehicule";
CM_ SG_ 1616 Sens_roue_ARG "Sens de roulage du vehicule";
CM_ SG_ 1616 Compteur_id_650 "compteur de 0 à 15 (0-F)";
CM_ BO_ 1617 "boitier FH vers PC robotisation";
CM_ SG_ 1617 Vit_roue_AVG "Vitesse de la roue";
CM_ SG_ 1617 Vit_roue_AVD "Vitesse de la roue";
CM_ SG_ 1617 Pedale_accel_enfoncement "Position mesurée de la pedale";
CM_ SG_ 1617 Pedale_frein_enfoncement "Position mesurée du frein";
CM_ SG_ 1617 Compteur_id_651 "compteur de 0 à 15 (0-F)";
CM_ BO_ 1618 "boitier FH vers PC robotisation";
CM_ SG_ 1618 FeuxVeilleuses_commodo "Etat des feux";
CM_ SG_ 1618 FeuxCodes_commodo "Etat des feux";
CM_ SG_ 1618 FeuxRoute_commodo "Etat des feux";
CM_ SG_ 1618 FeuxBrouillardAR_commodo "Etat des feux";
CM_ SG_ 1618 FeuxClignotantG_commodo "Etat des feux";
CM_ SG_ 1618 FeuxClignotantD_commodo "Etat des feux";
CM_ SG_ 1618 FeuxWarning_commodo "Etat des feux";
CM_ SG_ 1618 FeuxVeilleuses_etat "Etat des feux";
CM_ SG_ 1618 FeuxCodes_etat "Etat des feux";
CM_ SG_ 1618 FeuxRoute_etat "Etat des feux";
CM_ SG_ 1618 FeuxBrouillardAR_etat "Etat des feux";
CM_ SG_ 1618 FeuxClignotantG_etat "Etat des feux";
CM_ SG_ 1618 FeuxClignotantD_etat "Etat des feux";
CM_ SG_ 1618 FeuxWarning_etat "Etat des feux";
CM_ SG_ 1618 OuvrantPortiereAVG_etat "Etat de l ouvrant";
CM_ SG_ 1618 OuvrantPortiereAVD_etat "Etat de l ouvrant";
CM_ SG_ 1618 OuvrantPortiereARG_etat "Etat de l ouvrant";
CM_ SG_ 1618 OuvrantPortiereARD_etat "Etat de l ouvrant";
CM_ SG_ 1618 OuvrantCoffreAR_etat "Etat de l ouvrant";
CM_ SG_ 1618 CeintureSecurite_ConducteuEnSecu "Etat de la ceinture";
CM_ SG_ 1618 CeintureSecurite_PassagerEnSecu "Etat de la ceinture";
CM_ SG_ 1618 CeintureSecurite_ARG "Etat de la ceinture";
CM_ SG_ 1618 CeintureSecurite_ARD "Etat de la ceinture";
CM_ SG_ 1618 CeintureSecurite_ARC "Etat de la ceinture";
CM_ SG_ 1618 EssuiesGlaceVitPetite_commodo "Etat des Essuies glace";
CM_ SG_ 1618 EssuiesGlaceVitGrande_commodo "Etat des Essuies glace";
CM_ SG_ 1618 EssuiesGlaceVitPetite_etat "Etat des Essuies glace";
CM_ SG_ 1618 EssuiesGlaceVitGrande_etat "Etat des Essuies glace";
CM_ SG_ 1618 Position_RNDB "Position du RNDB";
CM_ SG_ 1618 Etat_pedale_Frein "etat de la pedale de frein";
CM_ SG_ 1618 Etat_pedale_Accel "etat de la pedale d accelerateur";
CM_ SG_ 1618 Etat_Frein_a_main "etat du frein a main";
CM_ SG_ 1618 Compteur_id_652 "compteur de 0 à 15 (0-F)";
CM_ BO_ 1911 "trame test UCA";
CM_ BO_ 1912 "trame test UCA";
CM_ BO_ 1913 "trame test UCA";

BA_DEF_ BO_  "GenMsgCycleTime" INT 0 65535;
BA_DEF_ SG_  "GenSigStartValue" FLOAT -3.4E+038 3.4E+038;

BA_DEF_DEF_  "GenMsgCycleTime" 0;
BA_DEF_DEF_  "GenSigStartValue" 0;

BA_ "GenMsgCycleTime" BO_ 256 2;

BA_ "GenSigStartValue" SG_ 256 Cons_DAE_Autonome 7200;
BA_ "GenSigStartValue" SG_ 272 Position_DAE 7200;
BA_ "GenSigStartValue" SG_ 272 Ecart_pos_DAE__cons_pos 7200;
BA_ "GenSigStartValue" SG_ 272 Couple_volant_mesure_DAE 2000;
BA_ "GenSigStartValue" SG_ 272 Couple_volant_genere_DAE 2000;
BA_ "GenSigStartValue" SG_ 273 Butee_maxi_DAE_G_autorise 7200;
BA_ "GenSigStartValue" SG_ 273 Butee_maxi_DAE_D_autorise 7200;

VAL_ 80 Mode_desire 0 "mode_manuel" 1 "mode_robotise" 2 "mode_cooperatif" 3 "mode_Selecteur_conducteur" ;
VAL_ 80 Activation_DAE_robotise_CAN 0 "0 - desactive" 1 "1 - active" ;
VAL_ 80 Activation_Accel_robotise_CAN 0 "0 - desactive" 1 "1 - active" ;
VAL_ 80 Activation_Frein_robotise_CAN 0 "0 - desactive" 1 "1 - active" ;
VAL_ 80 Activation_RNDB_robotise_CAN 0 "0 - desactive" 1 "1 - active" ;
VAL_ 80 Activation_Cligno_robotise_CAN 0 "0 - desactive" 1 "1 - active" ;
VAL_ 96 CondActiv_GenVehRobotisation 0 "valide - condition generale valide" 1 "non valide - condition generale non valide" ;
VAL_ 96 CauseNonActiv_Gen_PorteAVG 0 "valide - porte fermee" 1 "non valide - porte ouverte" ;
VAL_ 96 CauseNonActiv_Gen_PorteAVD 0 "valide - porte fermee" 1 "non valide - porte ouverte" ;
VAL_ 96 CauseNonActiv_Gen_PorteARG 0 "valide - porte fermee" 1 "non valide - porte ouverte" ;
VAL_ 96 CauseNonActiv_Gen_PorteARD 0 "valide - porte fermee" 1 "non valide - porte ouverte" ;
VAL_ 96 CauseNonActiv_Gen_RNDB 0 "position RNDB valide" 1 "position RNDB non valide" ;
VAL_ 96 CauseNonActiv_Gen_FreinMain 0 "valide - frein deserer" 1 "non valide - frein serer" ;
VAL_ 96 CauseNonActiv_Gen_ArretUrgence 0 "valide - Arret Urgence desactive" 1 "non valide - Arret Urgence actif" ;
VAL_ 96 CauseNonActiv_Gen_Porte_hayon 0 "valide - porte fermee" 1 "non valide - porte ouverte" ;
VAL_ 96 CauseNonActiv_Gen_SecuConducte 0 "0 - valide" 1 "1 - non valide" ;
VAL_ 96 CauseNonActiv_Gen_SecuPassager 0 "0 - valide" 1 "1 - non valide" ;
VAL_ 96 CauseNonActiv_Gen_CAN_intersys 0 "0 - valide" 1 "1 - non valide" ;
VAL_ 96 CauseNonActiv_Gen_ArretUrgen_UCA 0 "0 - Pas Arret Urgence" 1 "1 - Arret Urgence deporté enclenche" 2 "2 - Arret Urgence principal enclenche" 3 "3 - Arret Urgence principal et deporté enclenches" 4 "4 - Arret Urgence court circuit masse" 5 "5 - Arret Urgence debranche" ;
VAL_ 112 Pupitre_Rotacteur_mode 0 "mode_manuel" 1 "mode_robotise" 2 "mode_cooperatif" 3 "mode_Selecteur_conducteur" ;
VAL_ 112 Pupitre_interr_DAE 0 "0 - Off" 1 "1 - On" ;
VAL_ 112 Pupitre_interr_Accel 0 "0 - Off" 1 "1 - On" ;
VAL_ 112 Pupitre_interr_Frein 0 "0 - Off" 1 "1 - On" ;
VAL_ 112 Pupitre_interr_RNDB 0 "0 - Off" 1 "1 - On" ;
VAL_ 112 Pupitre_LED_Accel 0 "0 - Off" 1 "1 - On" ;
VAL_ 112 Pupitre_LED_Frein 0 "0 - Off" 1 "1 - On" ;
VAL_ 112 Pupitre_LED_DAE 0 "0 - Off" 1 "1 - On" ;
VAL_ 112 Pupitre_LED_RNDB 0 "0 - Off" 1 "1 - On" ;
VAL_ 112 Pupitre_LED_Defaut 0 "0 - Off" 1 "1 - On" ;
VAL_ 256 reactivation_mode_cooperatif_DAE 0 "0 - pas de demande de reactivation DAE en cooperatif" 1 "1 - demande de reactivation DAE en cooperatif" ;
VAL_ 272 Mode_DAE_en_cours 0 "mode_manuel" 1 "mode_robotise" 2 "mode_cooperatif" 3 "mode_Selecteur_conducteur" ;
VAL_ 272 DAE_Robotisable_plage_ok 0 "0 - DAE plage non OK pour activation robotisation ou cooperatif" 1 "1 - DAE plage OK pour activation robotisation ou cooperatif" ;
VAL_ 273 ErreurButeeDAE_gauche_atteinte 0 "0 : pas en erreur" 1 "1 : en erreur" ;
VAL_ 273 ErreurButeeDAE_droite_atteinte 0 "0 : pas en erreur" 1 "1 : en erreur" ;
VAL_ 273 ErreurCaptDAE_origine_couple_1 0 "0 : pas en erreur" 1 "1 : en erreur" ;
VAL_ 273 ErreurCapteur_DAE_incoh_sign1_2 0 "0 : pas en erreur" 1 "1 : en erreur" ;
VAL_ 273 ErreurPerte_CAN_intersystem_DAE 0 "0 : pas en erreur" 1 "1 : en erreur" ;
VAL_ 273 CauseDesactDAE_RepriseManu 0 "0 : Robotisation non desactivee par cette cause" 1 "1 : Robotisation desactivee par cette cause" ;
VAL_ 273 CauseDesactDAE_RepriseExterne 0 "0 : Robotisation non desactivee par cette cause" 1 "1 : Robotisation desactivee par cette cause" ;
VAL_ 273 CauseDesactDAE_PbCANRot_timeout 0 "0 : Robotisation non desactivee par cette cause" 1 "1 : Robotisation desactivee par cette cause" ;
VAL_ 273 CauseDesactDAE_PbCANRob_chk 0 "0 : Robotisation non desactivee par cette cause" 1 "1 : Robotisation desactivee par cette cause" ;
VAL_ 273 CauseDesactDAE_PbCANRob_Cpt 0 "0 : Robotisation non desactivee par cette cause" 1 "1 : Robotisation desactivee par cette cause" ;
VAL_ 273 CauseDesactDAE_PbCapteurOri 0 "0 : Robotisation non desactivee par cette cause" 1 "1 : Robotisation desactivee par cette cause" ;
VAL_ 273 CauseDesactDAE_RepriseManuCoop 0 "0 : Robotisation non desactivee par cette cause" 1 "1 : Robotisation desactivee par cette cause" ;
VAL_ 273 DAE_DmdPilotageLED 0 "0 - LED eteinte = pas de robotisation" 1 "1 - LED allumee = robotisation en cours" 2 "2 - LED etat 2 = val non utilise" ;
VAL_ 273 DAE_DmdPilotageBuzzer 0 "0 - Buzzer pas de demande" 1 "1 - Buzzer 2 bip court" 2 "2 - Buzzer bip long" 3 "3 - Buzzer 5 bip court" ;
VAL_ 273 DAE_DmdPilotageLED_Dft 0 "0 - LED eteinte = pas de defaut" 1 "1 - LED allumee = defaut capteur ou defaut CAN Veh" 2 "2 - LED clignotante rapide= arret urgence active" 3 "3 - LED clignotante lent =defaut CAN robotisation" ;
VAL_ 528 Mode_Accel_en_cours 0 "mode_manuel" 1 "mode_robotise" 2 "mode_cooperatif" 3 "mode_Selecteur_conducteur" ;
VAL_ 529 ErreurCapteur_Accel_origine 0 "0 : pas en erreur" 1 "1 : en erreur" ;
VAL_ 529 ErreurCapteur_Accel_incoh_ped1_2 0 "0 : pas en erreur" 1 "1 : en erreur" ;
VAL_ 529 ErreurPerte_CAN_intersystem_Acce 0 "0 : pas en erreur" 1 "1 : en erreur" ;
VAL_ 529 CauseDesactAccel_RepriseManu 0 "0 : Robotisation non desactivee par cette cause" 1 "1 : Robotisation desactivee par cette cause" ;
VAL_ 529 CauseDesactAccel_RepriseExterne 0 "0 : Robotisation non desactivee par cette cause" 1 "1 : Robotisation desactivee par cette cause" ;
VAL_ 529 CauseDesactAccel_PbCANRob_timeou 0 "0 : Robotisation non desactivee par cette cause" 1 "1 : Robotisation desactivee par cette cause" ;
VAL_ 529 CauseDesactAccel_PbCANRob_chk 0 "0 : Robotisation non desactivee par cette cause" 1 "1 : Robotisation desactivee par cette cause" ;
VAL_ 529 CauseDesactAccel_PbCANRot_Cpt 0 "0 : Robotisation non desactivee par cette cause" 1 "1 : Robotisation desactivee par cette cause" ;
VAL_ 529 CauseDesactAccel_PbCapteurOri 0 "0 : Robotisation non desactivee par cette cause" 1 "1 : Robotisation desactivee par cette cause" ;
VAL_ 529 CauseDesactAccel_RepriseManuCoop 0 "0 : Robotisation non desactivee par cette cause" 1 "1 : Robotisation desactivee par cette cause" ;
VAL_ 529 Accel_DmdPilotageLED 0 "0 - LED eteinte = pas de robotisation" 1 "1 - LED allumee = robotisation en cours" 2 "2 - LED etat 2 = val non utilise" ;
VAL_ 529 Accel_DmdPilotageBuzzer 0 "0 - Buzzer pas de demande" 1 "1 - Buzzer 2 bip court" 2 "2 - Buzzer bip long" 3 "3 - Buzzer 5 bip court" ;
VAL_ 529 Accel_DmdPilotageLED_Dft 0 "0 - LED eteinte = pas de defaut" 1 "1 - LED allumee = defaut capteur ou defaut CAN Veh" 2 "2 - LED clignotante rapide= arret urgence active" 3 "3 - LED clignotante lent =defaut CAN robotisation" ;
VAL_ 668 Sens_roulage_ARD 0 "0 - arret ou marche arriere" 1 "1 - marche avant" ;
VAL_ 784 Mode_Frein_en_cours 0 "mode_manuel" 1 "mode_robotise" 2 "mode_cooperatif" 3 "mode_Selecteur_conducteur" ;
VAL_ 785 ErreurCapteur_Frein_origine 0 "0 : pas en erreur" 1 "1 : en erreur" ;
VAL_ 785 ErreurCapteur_Frein_incoh_ped1_2 0 "0 : pas en erreur" 1 "1 : en erreur" ;
VAL_ 785 ErreurPerte_CAN_intersystem_Frei 0 "0 : pas en erreur" 1 "1 : en erreur" ;
VAL_ 785 CauseDesactFrein_RepriseManu 0 "0 : Robotisation non desactivee par cette cause" 1 "1 : Robotisation desactivee par cette cause" ;
VAL_ 785 CauseDesactFrein_RepriseExterne 0 "0 : Robotisation non desactivee par cette cause" 1 "1 : Robotisation desactivee par cette cause" ;
VAL_ 785 CauseDesactFrein_PbCANRob_timeou 0 "0 : Robotisation non desactivee par cette cause" 1 "1 : Robotisation desactivee par cette cause" ;
VAL_ 785 CauseDesactFrein_PbCANRob_chk 0 "0 : Robotisation non desactivee par cette cause" 1 "1 : Robotisation desactivee par cette cause" ;
VAL_ 785 CauseDesactFrein_PbCANRot_Cpt 0 "0 : Robotisation non desactivee par cette cause" 1 "1 : Robotisation desactivee par cette cause" ;
VAL_ 785 CauseDesactFrein_PbCapteurOri 0 "0 : Robotisation non desactivee par cette cause" 1 "1 : Robotisation desactivee par cette cause" ;
VAL_ 785 CauseDesactFrein_RepriseManuCoop 0 "0 : Robotisation non desactivee par cette cause" 1 "1 : Robotisation desactivee par cette cause" ;
VAL_ 785 Frein_DmdPilotageLED 0 "0 - LED eteinte = pas de robotisation" 1 "1 - LED allumee = robotisation en cours" 2 "2 - LED etat 2 = val non utilise" ;
VAL_ 785 Frein_DmdPilotageBuzzer 0 "0 - Buzzer pas de demande" 1 "1 - Buzzer 2 bip court" 2 "2 - Buzzer bip long" 3 "3 - Buzzer 5 bip court" ;
VAL_ 785 Frein_DmdPilotageLED_Dft 0 "0 - LED eteinte = pas de defaut" 1 "1 - LED allumee = defaut capteur ou defaut CAN Veh" 2 "2 - LED clignotante rapide= arret urgence active" 3 "3 - LED clignotante lent =defaut CAN robotisation" ;
VAL_ 1024 Cons_RNDB_robotise 1 "1 : R" 2 "2 : N" 3 "3 : D" 4 "4 : B" ;
VAL_ 1024 RNDB_Redemande_ChangementInvalid 0 "0 - pas de redemande Changement invalide precedent" 1 "1 - redemande Changement invalide precedent" ;
VAL_ 1040 RNDB_engage_mesure 1 "1 : R" 2 "2 : N" 3 "3 : D" 4 "4 : B" ;
VAL_ 1040 RNDB_engage_genere 1 "1 : R" 2 "2 : N" 3 "3 : D" 4 "4 : B" ;
VAL_ 1040 RNDB_ChangementValide 0 "0 - dernier changement non valide" 1 "1 - dernier changement valide" ;
VAL_ 1040 RNDB_ChangementInvalidePiedFrein 0 "0 - changement valide" 1 "1 - changement invalide manque pied frein" ;
VAL_ 1040 RNDB_ChangementInvalideRenault 0 "0 - changement valide par Renault" 1 "1 - changement non valide par Renault" ;
VAL_ 1040 Mode_RNDB_en_cours 0 "mode_manuel" 1 "mode_robotise" 2 "mode_cooperatif" 3 "mode_Selecteur_conducteur" ;
VAL_ 1041 ErreurCapteur_RNDB_origine 0 "0 : pas en erreur" 1 "1 : en erreur" ;
VAL_ 1041 ErreurCapteur_RNDB_incoh_ped1_2 0 "0 : pas en erreur" 1 "1 : en erreur" ;
VAL_ 1041 ErreurPerte_CAN_intersystem_RNDB 0 "0 : pas en erreur" 1 "1 : en erreur" ;
VAL_ 1041 CauseDesactRNDB_RepriseManu 0 "0 : Robotisation non desactivee par cette cause" 1 "1 : Robotisation desactivee par cette cause" ;
VAL_ 1041 CauseDesactRNDB_RepriseExterne 0 "0 : Robotisation non desactivee par cette cause" 1 "1 : Robotisation desactivee par cette cause" ;
VAL_ 1041 CauseDesactRNDB_PbCANRob_timeou 0 "0 : Robotisation non desactivee par cette cause" 1 "1 : Robotisation desactivee par cette cause" ;
VAL_ 1041 CauseDesactRNDB_PbCANRob_chk 0 "0 : Robotisation non desactivee par cette cause" 1 "1 : Robotisation desactivee par cette cause" ;
VAL_ 1041 CauseDesactRNDB_PbCANRot_Cpt 0 "0 : Robotisation non desactivee par cette cause" 1 "1 : Robotisation desactivee par cette cause" ;
VAL_ 1041 CauseDesactRNDB_PbCapteurOri 0 "0 : Robotisation non desactivee par cette cause" 1 "1 : Robotisation desactivee par cette cause" ;
VAL_ 1041 CauseDesactRNDB_RepriseManuCoop 0 "0 : Robotisation non desactivee par cette cause" 1 "1 : Robotisation desactivee par cette cause" ;
VAL_ 1041 RNDB_DmdPilotageLED 0 "0 - LED eteinte = pas de robotisation" 1 "1 - LED allumee = robotisation en cours" 2 "2 - LED etat 2 = val non utilise" ;
VAL_ 1041 RNDB_DmdPilotageBuzzer 0 "0 - Buzzer pas de demande" 1 "1 - Buzzer 2 bip court" 2 "2 - Buzzer bip long" 3 "3 - Buzzer 5 bip court" ;
VAL_ 1041 RNDB_DmdPilotageLED_Dft 0 "0 - LED eteinte = pas de defaut" 1 "1 - LED allumee = defaut capteur ou defaut CAN Veh" 2 "2 - LED clignotante rapide= arret urgence active" 3 "3 - LED clignotante lent =defaut CAN robotisation" ;
VAL_ 1280 Cons_Clignotant_gauche 0 "0 - pas de demande de robotisation" 1 "1 - demande de robotisation" ;
VAL_ 1280 Cons_Clignotant_droit 0 "0 - pas de demande de robotisation" 1 "1 - demande de robotisation" ;
VAL_ 1280 Cons_Clignotant_warning 0 "0 - pas de demande de robotisation" 1 "1 - demande de robotisation" ;
VAL_ 1280 Cons_Klaxon 0 "0 - pas de demande de robotisation" 1 "1 - demande de robotisation" ;
VAL_ 1616 Sens_roue_ARD 0 "0 - arret" 1 "1 - marche avant" 2 "2 - marche arriere" ;
VAL_ 1616 Sens_roue_ARG 0 "0 - arret" 1 "1 - marche avant" 2 "2 - marche arriere" ;
VAL_ 1618 FeuxVeilleuses_commodo 0 "0 - Off" 1 "1 - On" ;
VAL_ 1618 FeuxCodes_commodo 0 "0 - Off" 1 "1 - On" ;
VAL_ 1618 FeuxRoute_commodo 0 "0 - Off" 1 "1 - On" ;
VAL_ 1618 FeuxBrouillardAR_commodo 0 "0 - Off" 1 "1 - On" ;
VAL_ 1618 FeuxClignotantG_commodo 0 "0 - Off" 1 "1 - On" ;
VAL_ 1618 FeuxClignotantD_commodo 0 "0 - Off" 1 "1 - On" ;
VAL_ 1618 FeuxWarning_commodo 0 "0 - Off" 1 "1 - On" ;
VAL_ 1618 FeuxVeilleuses_etat 0 "0 - Off" 1 "1 - On" ;
VAL_ 1618 FeuxCodes_etat 0 "0 - Off" 1 "1 - On" ;
VAL_ 1618 FeuxRoute_etat 0 "0 - Off" 1 "1 - On" ;
VAL_ 1618 FeuxBrouillardAR_etat 0 "0 - Off" 1 "1 - On" ;
VAL_ 1618 FeuxClignotantG_etat 0 "0 - Off" 1 "1 - On" ;
VAL_ 1618 FeuxClignotantD_etat 0 "0 - Off" 1 "1 - On" ;
VAL_ 1618 FeuxWarning_etat 0 "0 - Off" 1 "1 - On" ;
VAL_ 1618 OuvrantPortiereAVG_etat 0 "0 - ouvrant ferme" 1 "1 - ouvrant ouvert" ;
VAL_ 1618 OuvrantPortiereAVD_etat 0 "0 - ouvrant ferme" 1 "1 - ouvrant ouvert" ;
VAL_ 1618 OuvrantPortiereARG_etat 0 "0 - ouvrant ferme" 1 "1 - ouvrant ouvert" ;
VAL_ 1618 OuvrantPortiereARD_etat 0 "0 - ouvrant ferme" 1 "1 - ouvrant ouvert" ;
VAL_ 1618 OuvrantCoffreAR_etat 0 "0 - ouvrant ferme" 1 "1 - ouvrant ouvert" ;
VAL_ 1618 CeintureSecurite_ConducteuEnSecu 0 "0 - non securise" 1 "1 - en securise" ;
VAL_ 1618 CeintureSecurite_PassagerEnSecu 0 "0 - non securise" 1 "1 - en securise" ;
VAL_ 1618 CeintureSecurite_ARG 0 "0 - non securise" 1 "1 - en securise" ;
VAL_ 1618 CeintureSecurite_ARD 0 "0 - non securise" 1 "1 - en securise" ;
VAL_ 1618 CeintureSecurite_ARC 0 "0 - non securise" 1 "1 - en securise" ;
VAL_ 1618 EssuiesGlaceVitPetite_commodo 0 "0 - Off" 1 "1 - On" ;
VAL_ 1618 EssuiesGlaceVitGrande_commodo 0 "0 - Off" 1 "1 - On" ;
VAL_ 1618 EssuiesGlaceVitPetite_etat 0 "0 - Off" 1 "1 - On" ;
VAL_ 1618 EssuiesGlaceVitGrande_etat 0 "0 - Off" 1 "1 - On" ;
VAL_ 1618 Position_RNDB 1 "1 : R" 2 "2 : N" 3 "3 : D" 4 "4 : B" ;
VAL_ 1618 Etat_pedale_Frein 0 "0 - pedale relachee" 1 "1 - pedale appuyee" ;
VAL_ 1618 Etat_pedale_Accel 0 "0 - pedale relachee" 1 "1 - pedale appuyee" ;
VAL_ 1618 Etat_Frein_a_main 0 "0 - Frein a main non sere" 1 "1 - Frein a main sere" ;
